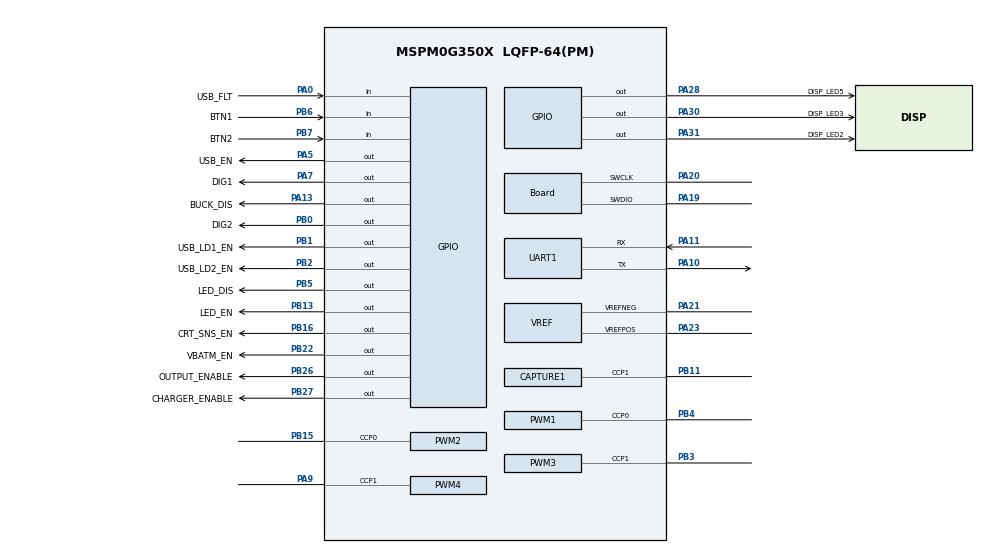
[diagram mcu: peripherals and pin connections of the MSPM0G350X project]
/**
 * @cliArgs --device "MSPM0G350X" --part "Default" --package "LQFP-64(PM)" --product "mspm0_sdk@2.02.00.05"
 * @versions {"tool":"1.21.0+3721"}
 */

/**
 * Import the modules used in this configuration.
 */
const ADC12         = scripting.addModule("/ti/driverlib/ADC12", {}, false);
const ADC121        = ADC12.addInstance();
const ADC122        = ADC12.addInstance();
const Board         = scripting.addModule("/ti/driverlib/Board");
const CAPTURE       = scripting.addModule("/ti/driverlib/CAPTURE", {}, false);
const CAPTURE1      = CAPTURE.addInstance();
const GPIO          = scripting.addModule("/ti/driverlib/GPIO", {}, false);
const GPIO1         = GPIO.addInstance();
const GPIO2         = GPIO.addInstance();
const GPIO3         = GPIO.addInstance();
const GPIO4         = GPIO.addInstance();
const PWM           = scripting.addModule("/ti/driverlib/PWM", {}, false);
const PWM1          = PWM.addInstance();
const PWM2          = PWM.addInstance();
const PWM3          = PWM.addInstance();
const PWM4          = PWM.addInstance();
const RTC           = scripting.addModule("/ti/driverlib/RTC");
const SYSCTL        = scripting.addModule("/ti/driverlib/SYSCTL");
const SYSTICK       = scripting.addModule("/ti/driverlib/SYSTICK");
const TIMER         = scripting.addModule("/ti/driverlib/TIMER", {}, false);
const TIMER1        = TIMER.addInstance();
const TIMER2        = TIMER.addInstance();
const UART          = scripting.addModule("/ti/driverlib/UART", {}, false);
const UART1         = UART.addInstance();
const VREF          = scripting.addModule("/ti/driverlib/VREF");
const ProjectConfig = scripting.addModule("/ti/project_config/ProjectConfig");

/**
 * Write custom configuration values to the imported modules.
 */
const divider4       = system.clockTree["PLL_CLK0_DIV"];
divider4.divideValue = 32;

const divider5       = system.clockTree["PLL_CLK1_DIV"];
divider5.divideValue = 32;

const gate8  = system.clockTree["MFPCLKGATE"];
gate8.enable = true;

const multiplier2         = system.clockTree["PLL_QDIV"];
multiplier2.multiplyValue = 4;

const mux2       = system.clockTree["CANCLKMUX"];
mux2.inputSelect = "CANCLKMUX_PLLCLK1_OUT";

const mux5       = system.clockTree["EXLFMUX"];
mux5.inputSelect = "EXLFMUX_XTAL";

const mux8       = system.clockTree["HSCLKMUX"];
mux8.inputSelect = "HSCLKMUX_SYSPLL0";

const pinFunction5     = system.clockTree["LFCLKEXT"];
pinFunction5.inputFreq = 32.768;

const pinFunction6     = system.clockTree["LFXT"];
pinFunction6.inputFreq = 32.768;

ADC121.$name                             = "ADC0";
ADC121.enableDMA                         = false;
ADC121.samplingOperationMode             = "sequence";
ADC121.adcMem1vref                       = "VREF";
ADC121.adcMem2vref                       = "VREF";
ADC121.adcMem3vref                       = "VREF";
ADC121.adcMem4vref                       = "VREF";
ADC121.adcMem5vref                       = "VREF";
ADC121.adcMem6vref                       = "VREF";
ADC121.adcMem8vref                       = "VREF";
ADC121.adcMem9chansel                    = "DL_ADC12_INPUT_CHAN_1";
ADC121.adcMem9vref                       = "VREF";
ADC121.adcMem9_name                      = "VCHG_M";
ADC121.enableHWAverage                   = true;
ADC121.adcMem1avgen                      = true;
ADC121.adcMem2avgen                      = true;
ADC121.adcMem3avgen                      = true;
ADC121.adcMem4avgen                      = true;
ADC121.adcMem5avgen                      = true;
ADC121.adcMem6avgen                      = true;
ADC121.adcMem7avgen                      = true;
ADC121.adcMem9avgen                      = true;
ADC121.sampleTime0                       = "50 us";
ADC121.adcMem2stime                      = "DL_ADC12_SAMPLE_TIMER_SOURCE_SCOMP1";
ADC121.adcMem3stime                      = "DL_ADC12_SAMPLE_TIMER_SOURCE_SCOMP1";
ADC121.adcMem4stime                      = "DL_ADC12_SAMPLE_TIMER_SOURCE_SCOMP1";
ADC121.adcMem6stime                      = "DL_ADC12_SAMPLE_TIMER_SOURCE_SCOMP1";
ADC121.adcMem9stime                      = "DL_ADC12_SAMPLE_TIMER_SOURCE_SCOMP1";
ADC121.sampleTime1                       = "150 us";
ADC121.adcMem0_name                      = "I_DISCHARGE";
ADC121.adcMem1chansel                    = "DL_ADC12_INPUT_CHAN_2";
ADC121.adcMem1_name                      = "3VOUT_M";
ADC121.adcMem2chansel                    = "DL_ADC12_INPUT_CHAN_5";
ADC121.adcMem2_name                      = "VBAT_M";
ADC121.adcMem3chansel                    = "DL_ADC12_INPUT_CHAN_6";
ADC121.adcMem4_name                      = "I_CHARGE";
ADC121.adcMem4chansel                    = "DL_ADC12_INPUT_CHAN_7";
ADC121.adcMem5chansel                    = "DL_ADC12_INPUT_CHAN_12";
ADC121.adcMem5_name                      = "I_PANEL";
ADC121.enabledInterrupts                 = ["DL_ADC12_INTERRUPT_MEM0_RESULT_LOADED","DL_ADC12_INTERRUPT_MEM5_RESULT_LOADED","DL_ADC12_INTERRUPT_MEM9_RESULT_LOADED"];
ADC121.adcMem6_name                      = "7";
ADC121.adcMem6chansel                    = "DL_ADC12_INPUT_CHAN_15";
ADC121.endAdd                            = 9;
ADC121.adcMem7chansel                    = "DL_ADC12_INPUT_CHAN_3";
ADC121.adcMem7_name                      = "V_USB_1";
ADC121.adcMem8_name                      = "V_USB_2";
ADC121.adcMem8chansel                    = "DL_ADC12_INPUT_CHAN_4";
ADC121.adcMem7vref                       = "VREF";
ADC121.adcMem0vref                       = "VREF";
ADC121.adcMem3_name                      = "TEMP3";
ADC121.adcMem0avgen                      = true;
ADC121.peripheral.$assign                = "ADC0";
ADC121.peripheral.adcPin0.$assign        = "PA27";
ADC121.peripheral.adcPin1.$assign        = "PA26";
ADC121.peripheral.adcPin2.$assign        = "PA25";
ADC121.peripheral.adcPin5.$assign        = "PB24";
ADC121.peripheral.adcPin6.$assign        = "PB20";
ADC121.peripheral.adcPin7.$assign        = "PA22";
ADC121.peripheral.adcPin12.$assign       = "PA14";
ADC121.peripheral.adcPin3.$assign        = "PA24";
ADC121.peripheral.adcPin4.$assign        = "PB25";
ADC121.adcPin0Config.hideOutputInversion = scripting.forceWrite(false);
ADC121.adcPin0Config.$name               = "ti_driverlib_gpio_GPIOPinGeneric16";
ADC121.adcPin1Config.$name               = "ti_driverlib_gpio_GPIOPinGeneric17";
ADC121.adcPin2Config.$name               = "ti_driverlib_gpio_GPIOPinGeneric4";
ADC121.adcPin5Config.$name               = "ti_driverlib_gpio_GPIOPinGeneric3";
ADC121.adcPin6Config.$name               = "ti_driverlib_gpio_GPIOPinGeneric5";
ADC121.adcPin7Config.$name               = "ti_driverlib_gpio_GPIOPinGeneric7";
ADC121.adcPin12Config.$name              = "ti_driverlib_gpio_GPIOPinGeneric6";
ADC121.adcPin3Config.$name               = "ti_driverlib_gpio_GPIOPinGeneric11";
ADC121.adcPin4Config.$name               = "ti_driverlib_gpio_GPIOPinGeneric13";

ADC122.enableDMA                         = false;
ADC122.sampClkSrc                        = "DL_ADC12_CLOCK_ULPCLK";
ADC122.$name                             = "ADC1";
ADC122.samplingOperationMode             = "sequence";
ADC122.adcMem1chansel                    = "DL_ADC12_INPUT_CHAN_1";
ADC122.adcMem2chansel                    = "DL_ADC12_INPUT_CHAN_2";
ADC122.adcMem5_name                      = "VBAT_M";
ADC122.adcMem5chansel                    = "DL_ADC12_INPUT_CHAN_6";
ADC122.adcMem1vref                       = "VREF";
ADC122.adcMem0vref                       = "VREF";
ADC122.adcMem2vref                       = "VREF";
ADC122.adcMem3vref                       = "VREF";
ADC122.adcMem4vref                       = "VREF";
ADC122.adcMem5vref                       = "VREF";
ADC122.adcMem6vref                       = "VREF";
ADC122.enableHWAverage                   = true;
ADC122.adcMem3avgen                      = true;
ADC122.adcMem4avgen                      = true;
ADC122.adcMem6avgen                      = true;
ADC122.sampleTime0                       = "50 us";
ADC122.adcMem5stime                      = "DL_ADC12_SAMPLE_TIMER_SOURCE_SCOMP1";
ADC122.sampleTime1                       = "150 us";
ADC122.adcMem0_name                      = "V_PANEL";
ADC122.adcMem2_name                      = "VLED2";
ADC122.adcMem3_name                      = "RSVD_PA18";
ADC122.adcMem4_name                      = "TEMP1";
ADC122.enabledInterrupts                 = ["DL_ADC12_INTERRUPT_MEM1_RESULT_LOADED","DL_ADC12_INTERRUPT_MEM2_RESULT_LOADED","DL_ADC12_INTERRUPT_MEM4_RESULT_LOADED","DL_ADC12_INTERRUPT_MEM6_RESULT_LOADED"];
ADC122.adcMem6_name                      = "";
ADC122.adcMem6chansel                    = "DL_ADC12_INPUT_CHAN_1";
ADC122.endAdd                            = 4;
ADC122.adcMem1_name                      = "V_LED1";
ADC122.adcMem4chansel                    = "DL_ADC12_INPUT_CHAN_4";
ADC122.adcMem3chansel                    = "DL_ADC12_INPUT_CHAN_3";
ADC122.peripheral.adcPin0.$assign        = "PA15";
ADC122.peripheral.adcPin1.$assign        = "PA16";
ADC122.peripheral.adcPin2.$assign        = "PA17";
ADC122.adcPin0Config.hideOutputInversion = scripting.forceWrite(false);
ADC122.adcPin0Config.$name               = "ti_driverlib_gpio_GPIOPinGeneric14";
ADC122.adcPin1Config.$name               = "ti_driverlib_gpio_GPIOPinGeneric9";
ADC122.adcPin2Config.$name               = "ti_driverlib_gpio_GPIOPinGeneric10";
ADC122.adcPin4Config.$name               = "ti_driverlib_gpio_GPIOPinGeneric8";
ADC122.adcPin3Config.$name               = "ti_driverlib_gpio_GPIOPinGeneric2";

Board.configureUnused             = true;
Board.peripheral.$assign          = "DEBUGSS";
Board.peripheral.swclkPin.$assign = "PA20";
Board.peripheral.swdioPin.$assign = "PA19";

CAPTURE1.$name                      = "B_INT";
CAPTURE1.ccIndex                    = 1;
CAPTURE1.interrupts                 = ["CC1_DN","ZERO"];
CAPTURE1.timerClkPrescale           = 10;
CAPTURE1.timerPeriod                = "150 ms";
CAPTURE1.peripheral.$assign         = "TIMG0";
CAPTURE1.peripheral.ccp1Pin.$assign = "PB11";
CAPTURE1.ccp1PinConfig.$name        = "ti_driverlib_gpio_GPIOPinGeneric27";

GPIO1.$name                                  = "EN";
GPIO1.associatedPins.create(11);
GPIO1.associatedPins[0].$name                = "BATTERY_ENABLE";
GPIO1.associatedPins[0].assignedPort         = "PORTB";
GPIO1.associatedPins[0].assignedPin          = "21";
GPIO1.associatedPins[1].$name                = "BUCK_DIS";
GPIO1.associatedPins[1].assignedPin          = "13";
GPIO1.associatedPins[1].assignedPort         = "PORTA";
GPIO1.associatedPins[1].pin.$assign          = "PA13";
GPIO1.associatedPins[2].$name                = "CHARGER_ENABLE";
GPIO1.associatedPins[2].assignedPortSegment  = "Upper";
GPIO1.associatedPins[2].assignedPort         = "PORTB";
GPIO1.associatedPins[2].assignedPin          = "27";
GPIO1.associatedPins[2].pin.$assign          = "PB27";
GPIO1.associatedPins[3].$name                = "OUTPUT_ENABLE";
GPIO1.associatedPins[3].assignedPortSegment  = "Upper";
GPIO1.associatedPins[3].assignedPort         = "PORTB";
GPIO1.associatedPins[3].assignedPin          = "26";
GPIO1.associatedPins[3].pin.$assign          = "PB26";
GPIO1.associatedPins[4].$name                = "VBATM_EN";
GPIO1.associatedPins[4].assignedPort         = "PORTB";
GPIO1.associatedPins[4].assignedPin          = "22";
GPIO1.associatedPins[4].pin.$assign          = "PB22";
GPIO1.associatedPins[5].assignedPortSegment  = "Lower";
GPIO1.associatedPins[5].assignedPort         = "PORTA";
GPIO1.associatedPins[5].assignedPin          = "5";
GPIO1.associatedPins[5].$name                = "USB_EN";
GPIO1.associatedPins[5].pin.$assign          = "PA5";
GPIO1.associatedPins[6].$name                = "LED_EN";
GPIO1.associatedPins[6].assignedPort         = "PORTB";
GPIO1.associatedPins[6].assignedPin          = "13";
GPIO1.associatedPins[6].pin.$assign          = "PB13";
GPIO1.associatedPins[7].$name                = "LED_DIS";
GPIO1.associatedPins[7].assignedPort         = "PORTB";
GPIO1.associatedPins[7].assignedPin          = "5";
GPIO1.associatedPins[7].pin.$assign          = "PB5";
GPIO1.associatedPins[8].$name                = "USB_LD1_EN";
GPIO1.associatedPins[8].assignedPort         = "PORTB";
GPIO1.associatedPins[8].assignedPin          = "1";
GPIO1.associatedPins[8].pin.$assign          = "PB1";
GPIO1.associatedPins[9].$name                = "USB_LD2_EN";
GPIO1.associatedPins[9].assignedPort         = "PORTB";
GPIO1.associatedPins[9].assignedPin          = "2";
GPIO1.associatedPins[9].pin.$assign          = "PB2";
GPIO1.associatedPins[10].$name               = "CRT_SNS_EN";
GPIO1.associatedPins[10].assignedPort        = "PORTB";
GPIO1.associatedPins[10].assignedPortSegment = "Upper";
GPIO1.associatedPins[10].assignedPin         = "16";
GPIO1.associatedPins[10].pin.$assign         = "PB16";

GPIO2.$name                              = "BTNS";
GPIO2.port                               = "PORTB";
GPIO2.associatedPins.create(2);
GPIO2.associatedPins[0].$name            = "BTN1";
GPIO2.associatedPins[0].direction        = "INPUT";
GPIO2.associatedPins[0].interruptEn      = true;
GPIO2.associatedPins[0].polarity         = "RISE_FALL";
GPIO2.associatedPins[0].internalResistor = "PULL_UP";
GPIO2.associatedPins[0].assignedPin      = "6";
GPIO2.associatedPins[0].pin.$assign      = "PB6";
GPIO2.associatedPins[1].$name            = "BTN2";
GPIO2.associatedPins[1].direction        = "INPUT";
GPIO2.associatedPins[1].interruptEn      = true;
GPIO2.associatedPins[1].polarity         = "RISE_FALL";
GPIO2.associatedPins[1].internalResistor = "PULL_UP";
GPIO2.associatedPins[1].assignedPin      = "7";
GPIO2.associatedPins[1].pin.$assign      = "PB7";

GPIO3.port                           = "PORTA";
GPIO3.$name                          = "FAULT";
GPIO3.associatedPins[0].$name        = "USB_FLT";
GPIO3.associatedPins[0].assignedPin  = "0";
GPIO3.associatedPins[0].initialValue = "SET";
GPIO3.associatedPins[0].direction    = "INPUT";
GPIO3.associatedPins[0].interruptEn  = true;
GPIO3.associatedPins[0].polarity     = "FALL";
GPIO3.associatedPins[0].pin.$assign  = "PA0";

GPIO4.$name                          = "DISP_CTRL";
GPIO4.associatedPins.create(7);
GPIO4.associatedPins[0].$name        = "DISP_LED1";
GPIO4.associatedPins[0].initialValue = "SET";
GPIO4.associatedPins[0].assignedPort = "PORTA";
GPIO4.associatedPins[0].assignedPin  = "3";
GPIO4.associatedPins[1].$name        = "DISP_LED2";
GPIO4.associatedPins[1].initialValue = "SET";
GPIO4.associatedPins[1].assignedPort = "PORTA";
GPIO4.associatedPins[1].assignedPin  = "31";
GPIO4.associatedPins[1].pin.$assign  = "PA31";
GPIO4.associatedPins[2].$name        = "DISP_LED3";
GPIO4.associatedPins[2].assignedPort = "PORTA";
GPIO4.associatedPins[2].assignedPin  = "30";
GPIO4.associatedPins[2].initialValue = "SET";
GPIO4.associatedPins[2].pin.$assign  = "PA30";
GPIO4.associatedPins[3].$name        = "DISP_LED4";
GPIO4.associatedPins[3].assignedPort = "PORTA";
GPIO4.associatedPins[3].assignedPin  = "29";
GPIO4.associatedPins[3].initialValue = "SET";
GPIO4.associatedPins[4].$name        = "DISP_LED5";
GPIO4.associatedPins[4].assignedPort = "PORTA";
GPIO4.associatedPins[4].assignedPin  = "28";
GPIO4.associatedPins[4].initialValue = "SET";
GPIO4.associatedPins[4].pin.$assign  = "PA28";
GPIO4.associatedPins[5].$name        = "DIG1";
GPIO4.associatedPins[5].assignedPort = "PORTA";
GPIO4.associatedPins[5].assignedPin  = "7";
GPIO4.associatedPins[5].initialValue = "SET";
GPIO4.associatedPins[5].pin.$assign  = "PA7";
GPIO4.associatedPins[6].$name        = "DIG2";
GPIO4.associatedPins[6].assignedPort = "PORTB";
GPIO4.associatedPins[6].assignedPin  = "0";
GPIO4.associatedPins[6].initialValue = "SET";
GPIO4.associatedPins[6].pin.$assign  = "PB0";

PWM1.timerCount                         = 100;
PWM1.ccIndex                            = [0];
PWM1.$name                              = "LEDCTRL_2";
PWM1.peripheral.$assign                 = "TIMA1";
PWM1.peripheral.ccp0Pin.$assign         = "PB4";
PWM1.PWM_CHANNEL_0.$name                = "ti_driverlib_pwm_PWMTimerCC3";
PWM1.PWM_CHANNEL_0.ccValue              = 99;
PWM1.ccp0PinConfig.direction            = scripting.forceWrite("OUTPUT");
PWM1.ccp0PinConfig.hideOutputInversion  = scripting.forceWrite(false);
PWM1.ccp0PinConfig.onlyInternalResistor = scripting.forceWrite(false);
PWM1.ccp0PinConfig.passedPeripheralType = scripting.forceWrite("Digital");
PWM1.ccp0PinConfig.$name                = "ti_driverlib_gpio_GPIOPinGeneric19";
PWM1.ccp0PinConfig.enableConfig         = true;
PWM1.ccp0PinConfig.internalResistor     = "PULL_DOWN";

PWM2.$name                              = "PWM_LED_OUTPUT";
PWM2.timerCount                         = 100;
PWM2.ccIndex                            = [0];
PWM2.peripheral.$assign                 = "TIMG7";
PWM2.peripheral.ccp0Pin.$assign         = "PB15";
PWM2.PWM_CHANNEL_0.$name                = "ti_driverlib_pwm_PWMTimerCC5";
PWM2.PWM_CHANNEL_0.ccValue              = 99;
PWM2.ccp0PinConfig.direction            = scripting.forceWrite("OUTPUT");
PWM2.ccp0PinConfig.hideOutputInversion  = scripting.forceWrite(false);
PWM2.ccp0PinConfig.onlyInternalResistor = scripting.forceWrite(false);
PWM2.ccp0PinConfig.passedPeripheralType = scripting.forceWrite("Digital");
PWM2.ccp0PinConfig.$name                = "ti_driverlib_gpio_GPIOPinGeneric20";
PWM2.ccp0PinConfig.enableConfig         = true;
PWM2.ccp0PinConfig.internalResistor     = "PULL_DOWN";

PWM3.$name                              = "PWM_VCHG";
PWM3.ccIndex                            = [1];
PWM3.timerCount                         = 400;
PWM3.peripheral.$assign                 = "TIMG6";
PWM3.peripheral.ccp1Pin.$assign         = "PB3";
PWM3.PWM_CHANNEL_1.$name                = "ti_driverlib_pwm_PWMTimerCC0";
PWM3.ccp1PinConfig.direction            = scripting.forceWrite("OUTPUT");
PWM3.ccp1PinConfig.hideOutputInversion  = scripting.forceWrite(false);
PWM3.ccp1PinConfig.onlyInternalResistor = scripting.forceWrite(false);
PWM3.ccp1PinConfig.passedPeripheralType = scripting.forceWrite("Digital");
PWM3.ccp1PinConfig.$name                = "ti_driverlib_gpio_GPIOPinGeneric12";

PWM4.timerCount                         = 100;
PWM4.ccIndex                            = [1];
PWM4.$name                              = "LEDCTRL_1";
PWM4.peripheral.$assign                 = "TIMA0";
PWM4.peripheral.ccp1Pin.$assign         = "PA9";
PWM4.ccp1PinConfig.direction            = scripting.forceWrite("OUTPUT");
PWM4.ccp1PinConfig.hideOutputInversion  = scripting.forceWrite(false);
PWM4.ccp1PinConfig.onlyInternalResistor = scripting.forceWrite(false);
PWM4.ccp1PinConfig.passedPeripheralType = scripting.forceWrite("Digital");
PWM4.ccp1PinConfig.$name                = "ti_driverlib_gpio_GPIOPinGeneric15";
PWM4.PWM_CHANNEL_1.$name                = "ti_driverlib_pwm_PWMTimerCC1";
PWM4.PWM_CHANNEL_1.ccValue              = 99;

RTC.calYear            = 2025;
RTC.enabledInterrupts  = ["READY"];
RTC.calDOW             = "2";
RTC.calDOM             = 29;
RTC.calMonth           = "7";
RTC.calHour            = 12;
RTC.calMin             = 59;
RTC.peripheral.$assign = "RTC";

SYSCTL.powerPolicy           = "STANDBY0";
SYSCTL.clockTreeEn           = true;
SYSCTL.forceDefaultClkConfig = true;

SYSTICK.periodEnable    = true;
SYSTICK.interruptEnable = true;
SYSTICK.systickEnable   = true;
SYSTICK.period          = 4000;

TIMER1.$name              = "B_INT_TIMER";
TIMER1.interrupts         = ["ZERO"];
TIMER1.timerPeriod        = "150 ms";
TIMER1.timerClkSrc        = "LFCLK";
TIMER1.peripheral.$assign = "TIMG12";

TIMER2.$name              = "ADC_LOW_POWER";
TIMER2.timerClkSrc        = "LFCLK";
TIMER2.timerClkDiv        = 8;
TIMER2.timerClkPrescale   = 256;
TIMER2.timerMode          = "PERIODIC";
TIMER2.timerPeriod        = "1s";
TIMER2.interrupts         = ["ZERO"];
TIMER2.peripheral.$assign = "TIMG8";

UART1.$name                    = "UART_0";
UART1.enabledInterrupts        = ["RX","TX"];
UART1.targetBaudRate           = 115200;
UART1.rxTimeoutValue           = 5;
UART1.peripheral.$assign       = "UART0";
UART1.peripheral.rxPin.$assign = "PA11";
UART1.peripheral.txPin.$assign = "PA10";
UART1.txPinConfig.$name        = "ti_driverlib_gpio_GPIOPinGeneric0";
UART1.rxPinConfig.$name        = "ti_driverlib_gpio_GPIOPinGeneric1";

VREF.checkVREFReady                = true;
VREF.basicIntVolt                  = "DL_VREF_BUFCONFIG_OUTPUT_2_5V";
VREF.advClkSrc                     = "DL_VREF_CLOCK_BUSCLK";
VREF.advClkDiv                     = "DL_VREF_CLOCK_DIVIDE_8";
VREF.advSHSample                   = 100;
VREF.advSHHold                     = 5000;
VREF.basicVrefPins                 = "VREF+-";
VREF.peripheral.$assign            = "VREF";
VREF.peripheral.vrefPosPin.$assign = "PA23";
VREF.peripheral.vrefNegPin.$assign = "PA21";
VREF.vrefPosPinConfig.$name        = "ti_driverlib_gpio_GPIOPinGeneric22";
VREF.vrefNegPinConfig.$name        = "ti_driverlib_gpio_GPIOPinGeneric25";

ProjectConfig.migrationCondition = true;

/**
 * Pinmux solution for unlocked pins/peripherals. This ensures that minor changes to the automatic solver in a future
 * version of the tool will not impact the pinmux you originally saw.  These lines can be completely deleted in order to
 * re-solve from scratch.
 */
ADC122.peripheral.$suggestSolution           = "ADC1";
ADC122.peripheral.adcPin4.$suggestSolution   = "PB17";
ADC122.peripheral.adcPin3.$suggestSolution   = "PA18";
GPIO1.associatedPins[0].pin.$suggestSolution = "PB21";
GPIO4.associatedPins[0].pin.$suggestSolution = "PA3";
GPIO4.associatedPins[3].pin.$suggestSolution = "PA29";
